# STM32WB50xx register map
File version: 1.0
Registers are 32-bit, read-write, reset 0x0 unless marked. A register's access mark holds for its fields unless they carry their own. Offsets are from the block's base; [hi:lo] are bit positions; lines under a group give offsets from that group; {n}, {i} and the like mark numbered series.

## ADC1 — Analog to Digital Converter
Base 0x50040000
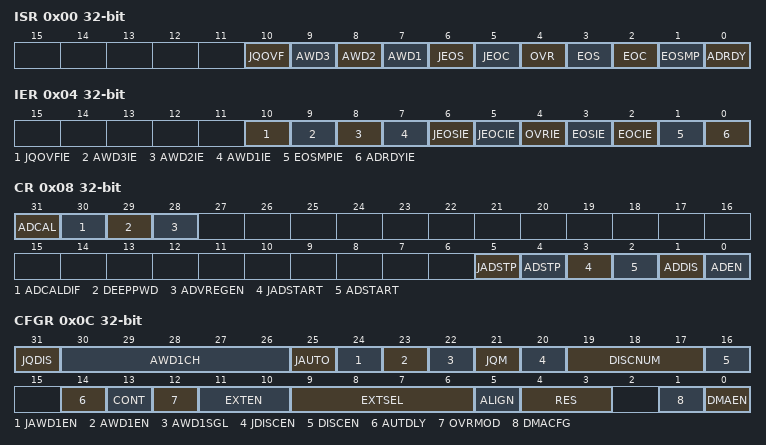
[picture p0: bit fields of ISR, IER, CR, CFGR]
0x00 ISR — ADC interrupt and status register
  [10] JQOVF — ADC group injected contexts queue overflow flag
  [9] AWD3 — ADC analog watchdog 3 flag
  [8] AWD2 — ADC analog watchdog 2 flag
  [7] AWD1 — ADC analog watchdog 1 flag
  [6] JEOS — ADC group injected end of sequence conversions flag
  [5] JEOC — ADC group injected end of unitary conversion flag
  [4] OVR — ADC group regular overrun flag
  [3] EOS — ADC group regular end of sequence conversions flag
  [2] EOC — ADC group regular end of unitary conversion flag
  [1] EOSMP — ADC group regular end of sampling flag
  [0] ADRDY — ADC ready flag
0x04 IER — ADC interrupt enable register
  [10] JQOVFIE — ADC group injected contexts queue overflow interrupt
  [9] AWD3IE — ADC analog watchdog 3 interrupt
  [8] AWD2IE — ADC analog watchdog 2 interrupt
  [7] AWD1IE — ADC analog watchdog 1 interrupt
  [6] JEOSIE — ADC group injected end of sequence conversions interrupt
  [5] JEOCIE — ADC group injected end of unitary conversion interrupt
  [4] OVRIE — ADC group regular overrun interrupt
  [3] EOSIE — ADC group regular end of sequence conversions interrupt
  [2] EOCIE — ADC group regular end of unitary conversion interrupt
  [1] EOSMPIE — ADC group regular end of sampling interrupt
  [0] ADRDYIE — ADC ready interrupt
0x08 CR — ADC control register
  [31] ADCAL — ADC calibration
  [30] ADCALDIF — ADC differential mode for calibration
  [29] DEEPPWD — ADC deep power down enable
  [28] ADVREGEN — ADC voltage regulator enable
  [5] JADSTP — ADC group injected conversion stop
  [4] ADSTP — ADC group regular conversion stop
  [3] JADSTART — ADC group injected conversion start
  [2] ADSTART — ADC group regular conversion start
  [1] ADDIS — ADC disable
  [0] ADEN — ADC enable
0x0C CFGR — ADC configuration register 1
  [31] JQDIS — ADC group injected contexts queue disable
  [30:26] AWD1CH — ADC analog watchdog 1 monitored channel selection
  [25] JAUTO — ADC group injected automatic trigger mode
    0=INDEPENDENT (ADC group injected conversion trigger independent. Setting mandatory if ADC group injected injected trigger source is set to an external trigger.); 1=FROM_GRP_REGULAR (ADC group injected conversion trigger from ADC group regular. Setting compliant only with group injected trigger source set to SW start, without any further action on ADC group injected conversion start or stop: in this case, ADC group injected is controlled only from ADC group regular.)
  [24] JAWD1EN — ADC analog watchdog 1 enable on scope ADC group injected
  [23] AWD1EN — ADC analog watchdog 1 enable on scope ADC group regular
  [22] AWD1SGL — ADC analog watchdog 1 monitoring a single channel or all channels
  [21] JQM — ADC group injected contexts queue mode
  [20] JDISCEN — ADC Discontinuous mode on injected channels
    0=DISABLE (ADC group injected sequencer discontinuous mode disable); 1=DISCONT_1RANK (ADC group injected sequencer discontinuous mode enable with sequence interruption every rank)
  [19:17] DISCNUM — ADC Discontinuous mode channel count
  [16] DISCEN — ADC group regular sequencer discontinuous mode
  [14] AUTDLY — ADC low power auto wait
  [13] CONT — ADC group regular continuous conversion mode
  [12] OVRMOD — ADC group regular overrun configuration
  [11:10] EXTEN — ADC group regular external trigger polarity
  [9:6] EXTSEL — ADC group regular external trigger source
  [5] ALIGN — ADC data alignment
  [4:3] RES — ADC data resolution
  [1] DMACFG — ADC DMA configuration
  [0] DMAEN — ADC DMA enable
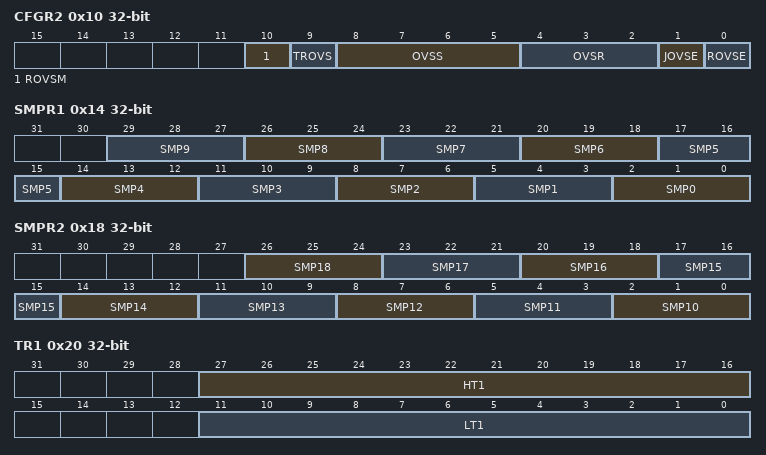
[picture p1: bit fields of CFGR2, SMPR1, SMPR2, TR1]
0x10 CFGR2 — ADC configuration register 2
  [10] ROVSM — ADC oversampling mode managing interlaced conversions of ADC group regular and group injected
  [9] TROVS — ADC oversampling discontinuous mode (triggered mode) for ADC group regular
  [8:5] OVSS — ADC oversampling shift
    0=NONE (ADC oversampling no shift (sum of the ADC conversions data is not divided to result as the ADC oversampling conversion data)); 1=RIGHT_1 (ADC oversampling shift of 1 (sum of the ADC conversions data is divided by 2 to result as the ADC oversampling conversion data)); 2=RIGHT_2 (ADC oversampling shift of 2 (sum of the ADC conversions data is divided by 4 to result as the ADC oversampling conversion data)); 3=RIGHT_3 (ADC oversampling shift of 3 (sum of the ADC conversions data is divided by 8 to result as the ADC oversampling conversion data)); 4=RIGHT_4 (ADC oversampling shift of 4 (sum of the ADC conversions data is divided by 16 to result as the ADC oversampling conversion data)); 5=RIGHT_5 (ADC oversampling shift of 5 (sum of the ADC conversions data is divided by 32 to result as the ADC oversampling conversion data)); 6=RIGHT_6 (ADC oversampling shift of 6 (sum of the ADC conversions data is divided by 64 to result as the ADC oversampling conversion data)); 7=RIGHT_7 (ADC oversampling shift of 7 (sum of the ADC conversions data is divided by 128 to result as the ADC oversampling conversion data)); 8=RIGHT_8 (ADC oversampling shift of 8 (sum of the ADC conversions data is divided by 256 to result as the ADC oversampling conversion data))
  [4:2] OVSR — ADC oversampling ratio
    0=RATIO_2 (ADC oversampling ratio of 2 (2 ADC conversions are performed, sum of these conversions data is computed to result as the ADC oversampling conversion data (before potential shift)); 1=RATIO_4 (ADC oversampling ratio of 4 (4 ADC conversions are performed, sum of these conversions data is computed to result as the ADC oversampling conversion data (before potential shift)); 2=RATIO_8 (ADC oversampling ratio of 8 (8 ADC conversions are performed, sum of these conversions data is computed to result as the ADC oversampling conversion data (before potential shift)); 3=RATIO_16 (ADC oversampling ratio of 16 (16 ADC conversions are performed, sum of these conversions data is computed to result as the ADC oversampling conversion data (before potential shift)); 4=RATIO_32 (ADC oversampling ratio of 32 (32 ADC conversions are performed, sum of these conversions data is computed to result as the ADC oversampling conversion data (before potential shift)); 5=RATIO_64 (ADC oversampling ratio of 64 (64 ADC conversions are performed, sum of these conversions data is computed to result as the ADC oversampling conversion data (before potential shift)); 6=RATIO_128 (ADC oversampling ratio of 128 (128 ADC conversions are performed, sum of these conversions data is computed to result as the ADC oversampling conversion data (before potential shift)); 7=RATIO_256 (ADC oversampling ratio of 256 (256 ADC conversions are performed, sum of these conversions data is computed to result as the ADC oversampling conversion data (before potential shift))
  [1] JOVSE — ADC oversampler enable on scope ADC group injected
  [0] ROVSE — ADC oversampler enable on scope ADC group regular
0x14 SMPR1 — ADC sampling time register 1
  [3n+2:3n] SMP{n} (n=0..9) — ADC channel {n} sampling time selection
0x18 SMPR2 — ADC sampling time register 2
  [3n-28:3n-30] SMP{n} (n=10..18) — ADC channel {n} sampling time selection
0x20 TR1 — ADC analog watchdog 1 threshold register
  [27:16] HT1 — ADC Analog watchdog 1 threshold high
  [11:0] LT1 — ADC analog watchdog 1 threshold low
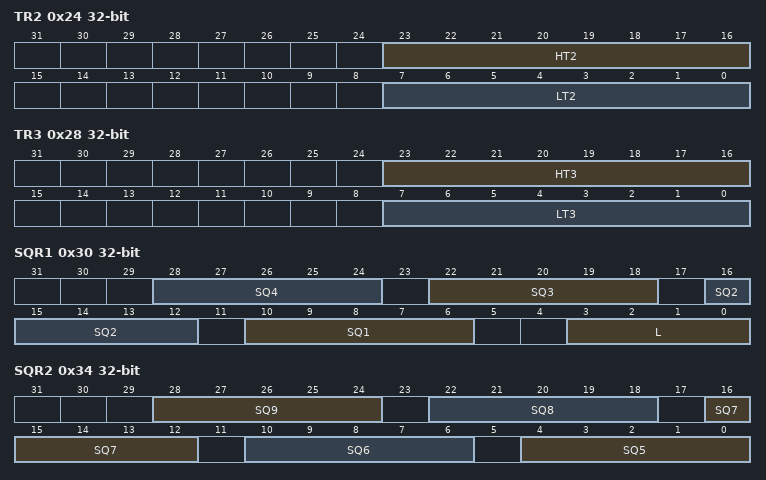
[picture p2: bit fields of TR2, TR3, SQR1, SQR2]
0x24 TR2 — ADC analog watchdog 2 threshold register
  [23:16] HT2 — ADC analog watchdog 2 threshold high
  [7:0] LT2 — ADC analog watchdog 2 threshold low
0x28 TR3 — ADC analog watchdog 3 threshold register
  [23:16] HT3 — ADC analog watchdog 3 threshold high
  [7:0] LT3 — ADC analog watchdog 3 threshold low
0x30 SQR1 — ADC group regular sequencer register 1
  [6n+4:6n] SQ{n} (n=1..4) — ADC group regular sequencer rank {n}
  [3:0] L — ADC group regular sequencer scan length
    0=DISABLE (ADC group regular sequencer disable (equivalent to sequencer of 1 rank: ADC conversion on only 1 channel)); {v}=ENABLE_{v+1}RANKS (ADC group regular sequencer enable with {v+1} ranks in the sequence) (v=1..15)
0x34 SQR2 — ADC group regular sequencer register 2
  [6n-26:6n-30] SQ{n} (n=5..9) — ADC group regular sequencer rank {n}
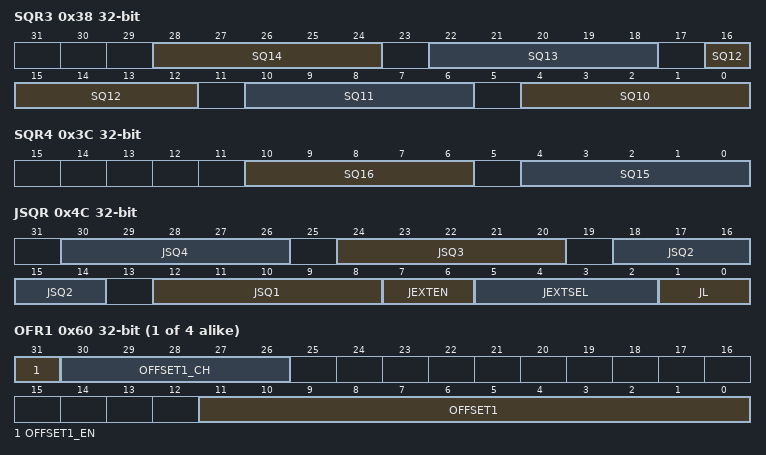
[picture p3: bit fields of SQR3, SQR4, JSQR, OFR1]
0x38 SQR3 — ADC group regular sequencer register 3
  [6n-56:6n-60] SQ{n} (n=10..14) — ADC group regular sequencer rank {n}
0x3C SQR4 — ADC group regular sequencer register 4
  [10:6] SQ16 — ADC group regular sequencer rank 16
  [4:0] SQ15 — ADC group regular sequencer rank 15
0x40 DR — ADC group regular data register
  [15:0] RDATA — ADC group regular conversion data
0x4C JSQR — ADC group injected sequencer register
  [6n+6:6n+2] JSQ{n} (n=1..4) — ADC group injected sequencer rank {n}
  [7:6] JEXTEN — ADC group injected external trigger polarity
    1=RISING (ADC group injected conversion trigger polarity set to rising edge); 2=FALLING (ADC group injected conversion trigger polarity set to falling edge); 3=RISINGFALLING (ADC group injected conversion trigger polarity set to both rising and falling edges)
  [5:2] JEXTSEL — ADC group injected external trigger source
  [1:0] JL — ADC group injected sequencer scan length
    0=DISABLE (ADC group injected sequencer disable (equivalent to sequencer of 1 rank: ADC conversion on only 1 channel)); 1=ENABLE_2RANKS (ADC group injected sequencer enable with 2 ranks in the sequence); 2=ENABLE_3RANKS (ADC group injected sequencer enable with 3 ranks in the sequence); 3=ENABLE_4RANKS (ADC group injected sequencer enable with 4 ranks in the sequence)
{0x5C+4i} OFR{i} (i=1..4) — ADC
  [31] OFFSET{i}_EN — ADC offset number {i} enable
  [30:26] OFFSET{i}_CH — ADC offset number {i} channel selection
  [11:0] OFFSET{i} — ADC offset number {i} offset level
{0x7C+4i} JDR{i} (i=1..4) — ADC group injected rank {i} data register
  [15:0] JDATA — ADC group injected sequencer rank {i} conversion data
0xA0 AWD2CR — ADC analog watchdog 1 configuration register
  [18:0] AWD2CH — ADC analog watchdog 2 monitored channel selection
0xA4 AWD3CR — ADC analog watchdog 3 Configuration Register
  [18:0] AWD3CH — ADC analog watchdog 3 monitored channel selection
0xB0 DIFSEL — ADC differential mode selection register
  [18:0] DIFSEL — ADC channel differential or single-ended mode
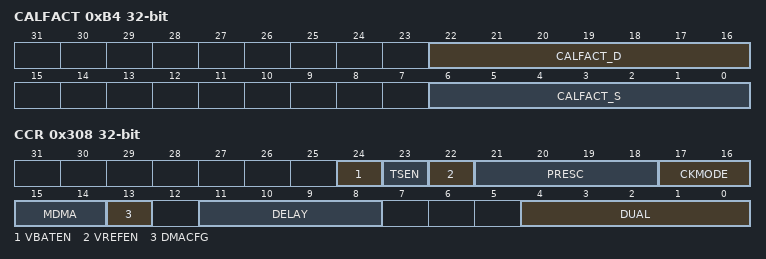
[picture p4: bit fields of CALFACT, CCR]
0xB4 CALFACT — ADC calibration factors
  [22:16] CALFACT_D — ADC calibration factor in differential mode
  [6:0] CALFACT_S — ADC calibration factor in single-ended mode
0x308 CCR — ADC common configuration register
  [24] VBATEN — ADC internal path to battery voltage enable
  [23] TSEN — ADC internal path to temperature sensor enable
  [22] VREFEN — ADC internal path to VrefInt enable
  [21:18] PRESC — ADC common clock prescaler, only for clock source asynchronous
  [17:16] CKMODE — ADC common clock source and prescaler (prescaler only for clock source synchronous)
  [15:14] MDMA — ADC multimode DMA transfer enable
  [13] DMACFG — ADC multimode DMA transfer configuration
  [11:8] DELAY — ADC multimode delay between 2 sampling phases
  [4:0] DUAL — ADC multimode mode selection
